# R7FA6M4AF register map
Vendor: Renesas Electronics Corporation; Series: RA6; File version: 1.30.00
CPU: CM33 r0p4, little endian, MPU, FPU, VTOR, 4 interrupt priority bits, 96 interrupts
Registers are 8-bit, read-write, reset 0x0 unless marked. A register's access mark holds for its fields unless they carry their own. Offsets are from the block's base; [hi:lo] are bit positions.

## SDHI0 — SD Host Interface 0
Base 0x40092000
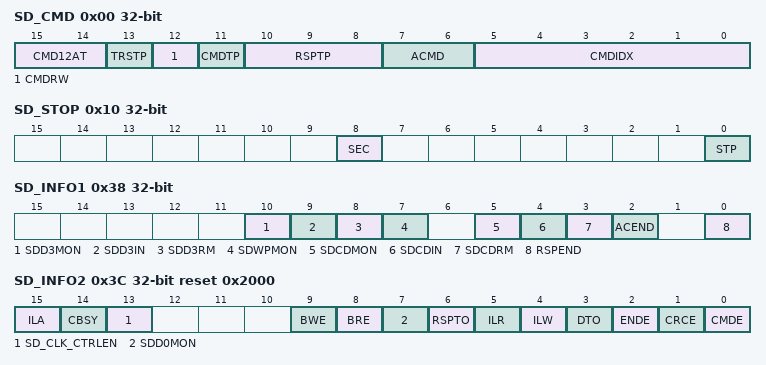
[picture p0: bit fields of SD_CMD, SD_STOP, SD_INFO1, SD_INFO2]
0x00 SD_CMD 32-bit — Command Type Register
  [15:14] CMD12AT — CMD12 Automatic Issue Select
  [13] TRSTP — Block Transfer Select
  [12] CMDRW — Data Transfer Direction Select
  [11] CMDTP — Data Transfer Select
  [10:8] RSPTP — Response Type Select
  [7:6] ACMD — Command Type Select
  [5:0] CMDIDX — Command Index Field Value Select
0x08 SD_ARG 32-bit — SD Command Argument Register
0x0C SD_ARG1 32-bit — SD Command Argument Register 1
0x10 SD_STOP 32-bit — Data Stop Register
  [8] SEC — Block Count Register Value Select
  [0] STP — Transfer Stop
0x14 SD_SECCNT 32-bit — Block Count Register
0x18 SD_RSP10 32-bit — SD Card Response Register 10
0x1C SD_RSP1 32-bit ro — SD Card Response Register 1
0x20 SD_RSP32 32-bit — SD Card Response Register 32
0x24 SD_RSP3 32-bit ro — SD Card Response Register 3
0x28 SD_RSP54 32-bit — SD Card Response Register 54
0x2C SD_RSP5 32-bit ro — SD Card Response Register 5
0x30 SD_RSP76 32-bit ro — SD Card Response Register 76
  [23:0] SD_RSP76 — These bits store the response from the SD card/MMC.
0x34 SD_RSP7 32-bit ro — SD Card Response Register 7
  [7:0] SD_RSP7 — These bits store the response from the SD card/MMC.
0x38 SD_INFO1 32-bit (reset mask 0xFFFFFB5F) — SD Card Interrupt Flag Register 1
  [10] SDD3MON ro — SDnDAT3 Pin Monitor Flag
  [9] SDD3IN — SDnDAT3 Insertion Flag
  [8] SDD3RM — SDnDAT3 Removal Flag
  [7] SDWPMON ro — SDnWP Pin Monitor Flag
  [5] SDCDMON ro — SDnCD Pin Monitor Flag
  [4] SDCDIN — SDnCD Insertion Flag
  [3] SDCDRM — SDnCD Removal Flag
  [2] ACEND — Access End Detection Flag
  [0] RSPEND — Response End Detection Flag
0x3C SD_INFO2 32-bit reset 0x2000 (reset mask 0xFFFFF77F) — SD Card Interrupt Flag Register 2
  [15] ILA — Illegal Access Error Detection Flag
  [14] CBSY ro — Command Sequence Status Flag
  [13] SD_CLK_CTRLEN ro — SD_CLK_CTRL Write Enable Flag
  [9] BWE — SD_BUF0 Write Enable Flag
  [8] BRE — SD_BUF0 Read Enable Flag
  [7] SDD0MON ro — SDnDAT0 Pin Status Flag
  [6] RSPTO — Response Timeout Detection Flag
  [5] ILR — SD_BUF0 Illegal Read Access Detection Flag
  [4] ILW — SD_BUF0 Illegal Write Access Detection Flag
  [3] DTO — Data Timeout Detection Flag
  [2] ENDE — End Bit Error Detection Flag
  [1] CRCE — CRC Error Detection Flag
  [0] CMDE — Command Error Detection Flag
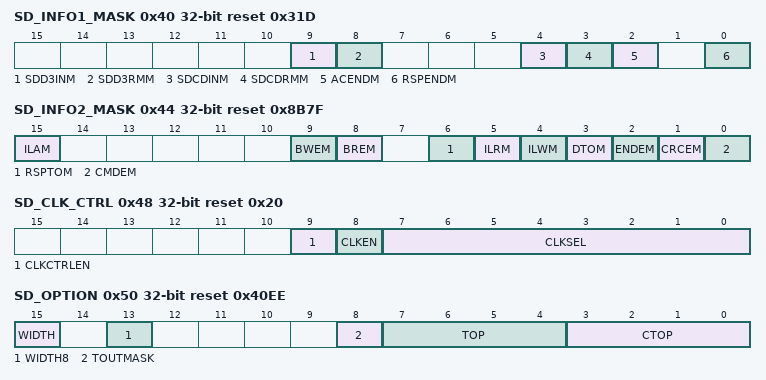
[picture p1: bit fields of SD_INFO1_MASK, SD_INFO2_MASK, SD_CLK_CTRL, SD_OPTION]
0x40 SD_INFO1_MASK 32-bit reset 0x31D — SD INFO1 Interrupt Mask Register
  [9] SDD3INM — SDnDAT3 Insertion Interrupt Request Mask
  [8] SDD3RMM — SDnDAT3 Removal Interrupt Request Mask
  [4] SDCDINM — SDnCD Insertion Interrupt Request Mask
  [3] SDCDRMM — SDnCD Removal Interrupt Request Mask
  [2] ACENDM — Access End Interrupt Request Mask
  [0] RSPENDM — Response End Interrupt Request Mask
0x44 SD_INFO2_MASK 32-bit reset 0x8B7F — SD INFO2 Interrupt Mask Register
  [15] ILAM — Illegal Access Error Interrupt Request Mask
  [9] BWEM — BWE Interrupt Request Mask
  [8] BREM — BRE Interrupt Request Mask
  [6] RSPTOM — Response Timeout Interrupt Request Mask
  [5] ILRM — SD_BUF0 Register Illegal Read Interrupt Request Mask
  [4] ILWM — SD_BUF0 Register Illegal Write Interrupt Request Mask
  [3] DTOM — Data Timeout Interrupt Request Mask
  [2] ENDEM — End Bit Error Interrupt Request Mask
  [1] CRCEM — CRC Error Interrupt Request Mask
  [0] CMDEM — Command Error Interrupt Request Mask
0x48 SD_CLK_CTRL 32-bit reset 0x20 — SD Clock Control Register
  [9] CLKCTRLEN — SD/MMC Clock Output Automatic Control Select
  [8] CLKEN — SD/MMC Clock Output Control
  [7:0] CLKSEL — SDHI Clock Frequency Select
0x4C SD_SIZE 32-bit reset 0x200 — Transfer Data Length Register
  [9:0] LEN — Transfer Data Size Setting
0x50 SD_OPTION 32-bit reset 0x40EE — SD Card Access Control Option Register
  [15] WIDTH — Bus Width
  [13] WIDTH8 — Bus Width
  [8] TOUTMASK — Timeout Mask
  [7:4] TOP — Timeout Counter
  [3:0] CTOP — Card Detection Time Counter
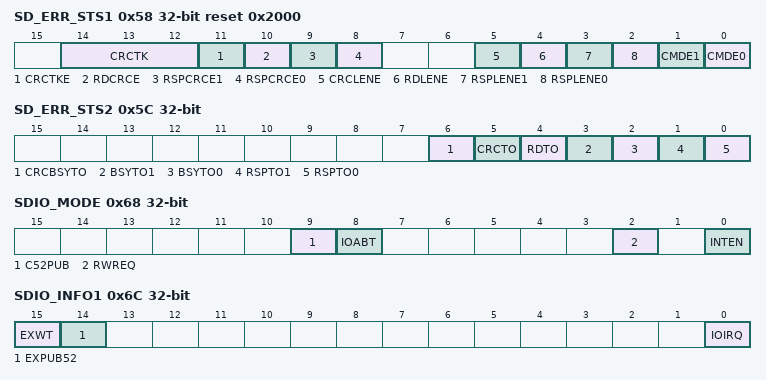
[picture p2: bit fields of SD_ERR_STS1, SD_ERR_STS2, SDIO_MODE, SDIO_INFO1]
0x58 SD_ERR_STS1 32-bit ro reset 0x2000 — SD Error Status Register 1
  [14:12] CRCTK — CRC Status Token
  [11] CRCTKE — CRC Status Token Error Flag
  [10] RDCRCE — Read Data CRC Error Flag
  [9] RSPCRCE1 — Response CRC Error Flag 1
  [8] RSPCRCE0 — Response CRC Error Flag 0
  [5] CRCLENE — CRC Status Token Length Error Flag
  [4] RDLENE — Read Data Length Error Flag
  [3] RSPLENE1 — Response Length Error Flag 1
  [2] RSPLENE0 — Response Length Error Flag 0
  [1] CMDE1 — Command Error Flag 1
  [0] CMDE0 — Command Error Flag 0
0x5C SD_ERR_STS2 32-bit ro — SD Error Status Register 2
  [6] CRCBSYTO — CRC Status Token Busy Timeout Flag
  [5] CRCTO — CRC Status Token Timeout Flag
  [4] RDTO — Read Data Timeout Flag
  [3] BSYTO1 — Busy Timeout Flag 1
  [2] BSYTO0 — Busy Timeout Flag 0
  [1] RSPTO1 — Response Timeout Flag 1
  [0] RSPTO0 — Response Timeout Flag 0
0x60 SD_BUF0 32-bit reset not defined — SD Buffer Register
0x68 SDIO_MODE 32-bit — SDIO Mode Control Register
  [9] C52PUB — SDIO None Abort
  [8] IOABT — SDIO Abort
  [2] RWREQ — Read Wait Request
  [0] INTEN — SDIO Interrupt Acceptance Enable
0x6C SDIO_INFO1 32-bit — SDIO Interrupt Flag Register
  [15] EXWT — EXWT Status Flag
  [14] EXPUB52 — EXPUB52 Status Flag
  [0] IOIRQ — SDIO Interrupt Status Flag
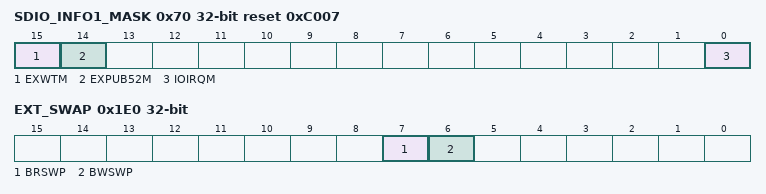
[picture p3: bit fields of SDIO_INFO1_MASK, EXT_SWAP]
0x70 SDIO_INFO1_MASK 32-bit reset 0xC007 — SDIO INFO1 Interrupt Mask Register
  [15] EXWTM — EXWT Interrupt Request Mask Control
  [14] EXPUB52M — EXPUB52 Interrupt Request Mask Control
  [0] IOIRQM — IOIRQ Interrupt Mask Control
0x1B0 SD_DMAEN 32-bit reset 0x1010 — DMA Mode Enable Register
  [1] DMAEN — DMA Transfer Enable
0x1C0 SOFT_RST 32-bit reset 0x7 — Software Reset Register
  [0] SDRST — Software Reset Control
0x1CC SDIF_MODE 32-bit — SD Interface Mode Setting Register
  [8] NOCHKCR — CRC Check Mask
0x1E0 EXT_SWAP 32-bit — Swap Control Register
  [7] BRSWP — SD_BUF0 Swap Read
  [6] BWSWP — SD_BUF0 Swap Write
